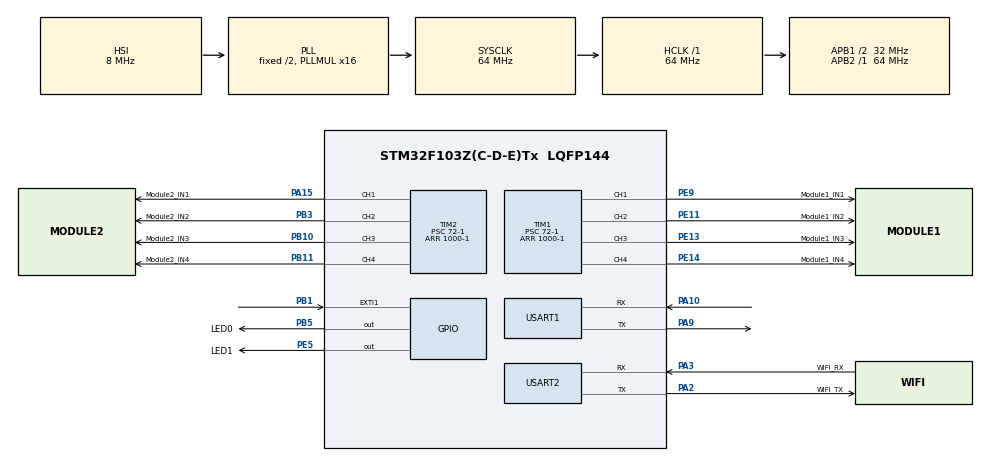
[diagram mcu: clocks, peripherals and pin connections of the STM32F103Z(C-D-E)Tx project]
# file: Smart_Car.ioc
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Dma.Request0=USART2_RX
Dma.USART2_RX.0.Direction=DMA_PERIPH_TO_MEMORY
Dma.USART2_RX.0.Instance=DMA1_Channel6
Dma.USART2_RX.0.MemDataAlignment=DMA_MDATAALIGN_BYTE
Dma.USART2_RX.0.MemInc=DMA_MINC_ENABLE
Dma.USART2_RX.0.Mode=DMA_NORMAL
Dma.USART2_RX.0.PeriphDataAlignment=DMA_PDATAALIGN_BYTE
Dma.USART2_RX.0.PeriphInc=DMA_PINC_DISABLE
Dma.USART2_RX.0.Priority=DMA_PRIORITY_LOW
Mcu.Family=STM32F1
Mcu.Name=STM32F103Z(C-D-E)Tx
Mcu.Package=LQFP144
NVIC.DMA1_Channel6_IRQn=true\:0\:0\:false\:false\:true\:false\:true
NVIC.PriorityGroup=NVIC_PRIORITYGROUP_4
NVIC.USART2_IRQn=true\:0\:0\:false\:false\:true\:true\:true
PA10.Mode=Asynchronous
PA10.Signal=USART1_RX
PA13.Mode=Serial_Wire
PA13.Signal=SYS_JTMS-SWDIO
PA14.Mode=Serial_Wire
PA14.Signal=SYS_JTCK-SWCLK
PA15.GPIO_Label=Module2_IN1
PA15.GPIO_Speed=GPIO_SPEED_FREQ_HIGH
PA15.Signal=S_TIM2_CH1_ETR
PA2.GPIO_Label=WIFI_TX
PA2.Mode=Asynchronous
PA2.Signal=USART2_TX
PA3.GPIO_Label=WIFI_RX
PA3.Mode=Asynchronous
PA3.Signal=USART2_RX
PA9.Mode=Asynchronous
PA9.Signal=USART1_TX
PB1.Signal=GPXTI1
PB10.GPIO_Label=Module2_IN3
PB10.GPIO_Speed=GPIO_SPEED_FREQ_HIGH
PB10.Signal=S_TIM2_CH3
PB11.GPIO_Label=Module2_IN4
PB11.GPIO_Speed=GPIO_SPEED_FREQ_HIGH
PB11.Signal=S_TIM2_CH4
PB3.GPIO_Label=Module2_IN2
PB3.GPIO_Speed=GPIO_SPEED_FREQ_HIGH
PB3.Signal=S_TIM2_CH2
PB5.GPIO_Label=LED0
PB5.GPIO_Speed=GPIO_SPEED_FREQ_HIGH
PB5.PinState=GPIO_PIN_SET
PB5.Signal=GPIO_Output
PE11.GPIO_Label=Module1_IN2
PE11.GPIO_Speed=GPIO_SPEED_FREQ_HIGH
PE11.Signal=S_TIM1_CH2
PE13.GPIO_Label=Module1_IN3
PE13.GPIO_Speed=GPIO_SPEED_FREQ_HIGH
PE13.Signal=S_TIM1_CH3
PE14.GPIO_Label=Module1_IN4
PE14.GPIO_Speed=GPIO_SPEED_FREQ_HIGH
PE14.Signal=S_TIM1_CH4
PE5.GPIO_Label=LED1
PE5.GPIO_Speed=GPIO_SPEED_FREQ_HIGH
PE5.PinState=GPIO_PIN_SET
PE5.Signal=GPIO_Output
PE9.GPIO_Label=Module1_IN1
PE9.GPIO_Speed=GPIO_SPEED_FREQ_HIGH
PE9.Signal=S_TIM1_CH1
ProjectManager.HeapSize=0x200
ProjectManager.StackSize=0x400
ProjectManager.TargetToolchain=MDK-ARM V5
RCC.AHBFreq_Value=64000000
RCC.APB1CLKDivider=RCC_HCLK_DIV2
RCC.APB1Freq_Value=32000000
RCC.APB1TimFreq_Value=64000000
RCC.APB2Freq_Value=64000000
RCC.APB2TimFreq_Value=64000000
RCC.HCLKFreq_Value=64000000
RCC.PLLMUL=RCC_PLL_MUL16
RCC.SYSCLKFreq_VALUE=64000000
RCC.SYSCLKSource=RCC_SYSCLKSOURCE_PLLCLK
RCC.USBFreq_Value=64000000
SH.S_TIM1_CH1.0=TIM1_CH1,PWM Generation1 CH1
SH.S_TIM1_CH2.0=TIM1_CH2,PWM Generation2 CH2
SH.S_TIM1_CH3.0=TIM1_CH3,PWM Generation3 CH3
SH.S_TIM1_CH4.0=TIM1_CH4,PWM Generation4 CH4
SH.S_TIM2_CH1_ETR.0=TIM2_CH1,PWM Generation1 CH1
SH.S_TIM2_CH2.0=TIM2_CH2,PWM Generation2 CH2
SH.S_TIM2_CH3.0=TIM2_CH3,PWM Generation3 CH3
SH.S_TIM2_CH4.0=TIM2_CH4,PWM Generation4 CH4
TIM1.Channel-PWM\ Generation1\ CH1=TIM_CHANNEL_1
TIM1.Channel-PWM\ Generation2\ CH2=TIM_CHANNEL_2
TIM1.Channel-PWM\ Generation3\ CH3=TIM_CHANNEL_3
TIM1.Channel-PWM\ Generation4\ CH4=TIM_CHANNEL_4
TIM1.Period=1000-1
TIM1.Prescaler=72-1
TIM2.Channel-PWM\ Generation1\ CH1=TIM_CHANNEL_1
TIM2.Channel-PWM\ Generation2\ CH2=TIM_CHANNEL_2
TIM2.Channel-PWM\ Generation3\ CH3=TIM_CHANNEL_3
TIM2.Channel-PWM\ Generation4\ CH4=TIM_CHANNEL_4
TIM2.Period=1000-1
TIM2.Prescaler=72-1
USART1.VirtualMode=VM_ASYNC
USART2.VirtualMode=VM_ASYNC
board=custom

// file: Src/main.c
/* USER CODE BEGIN Header */
/**
  ******************************************************************************
  * @file           : main.c
  * @brief          : Main program body
  ******************************************************************************
  * @attention
  *
  * <h2><center>&copy; Copyright (c) 2020 STMicroelectronics.
  * All rights reserved.</center></h2>
  *
  * This software component is licensed by ST under BSD 3-Clause license,
  * the "License"; You may not use this file except in compliance with the
  * License. You may obtain a copy of the License at:
  *                        opensource.org/licenses/BSD-3-Clause
  *
  ******************************************************************************
  */
/* USER CODE END Header */

#include "main.h"
#include "dma.h"
#include "tim.h"
#include "usart.h"
#include "gpio.h"

/* USER CODE BEGIN Includes */
#include "bsp_irda.h"
#include "esp8266.h"
/* USER CODE END Includes */

/* USER CODE BEGIN PV */
uint8_t isr_cnt;  /* 用于计算进了多少次中断 */
/* USER CODE END PV */

void SystemClock_Config(void);

/* USER CODE BEGIN 0 */
#define LED1_TOGGLE     HAL_GPIO_TogglePin(LED0_GPIO_Port,LED0_Pin)                // 输出反转

/* USER CODE END 0 */

int main(void)
{
    /* USER CODE BEGIN 1 */
    uint8_t key_val;
    /* USER CODE END 1 */

    /* MCU Configuration--------------------------------------------------------*/

    /* Reset of all peripherals, Initializes the Flash interface and the Systick. */
    HAL_Init();

    /* Configure the system clock */
    SystemClock_Config();

    /* Initialize all configured peripherals */
    MX_GPIO_Init();
    MX_DMA_Init();
    MX_USART1_UART_Init();
    MX_TIM1_Init();
    MX_TIM2_Init();
    MX_USART2_UART_Init();
    /* USER CODE BEGIN 2 */
    printf("ESP8266\n");
    //启动ESP8266
    wifi_send_cmd("AT+RST\r\n");
    Init_ESP8266_AP_Mode();
		HAL_GPIO_WritePin(LED1_GPIO_Port,LED1_Pin,GPIO_PIN_SET);
    /* USER CODE END 2 */

    /* Infinite loop */
    while (1)
    {

        /* USER CODE BEGIN 3 */
        ESP8266_AP_Mode_Setting();
        timer_loop();
    }

    /* USER CODE END 3 */
}

void SystemClock_Config(void)
{
    RCC_OscInitTypeDef RCC_OscInitStruct = {0};
    RCC_ClkInitTypeDef RCC_ClkInitStruct = {0};

    /** Initializes the CPU, AHB and APB busses clocks
    */
    RCC_OscInitStruct.OscillatorType = RCC_OSCILLATORTYPE_HSI;
    RCC_OscInitStruct.HSIState = RCC_HSI_ON;
    RCC_OscInitStruct.HSICalibrationValue = RCC_HSICALIBRATION_DEFAULT;
    RCC_OscInitStruct.PLL.PLLState = RCC_PLL_ON;
    RCC_OscInitStruct.PLL.PLLSource = RCC_PLLSOURCE_HSI_DIV2;
    RCC_OscInitStruct.PLL.PLLMUL = RCC_PLL_MUL16;

    if (HAL_RCC_OscConfig(&RCC_OscInitStruct) != HAL_OK)
    {
        Error_Handler();
    }

    /** Initializes the CPU, AHB and APB busses clocks
    */
    RCC_ClkInitStruct.ClockType = RCC_CLOCKTYPE_HCLK | RCC_CLOCKTYPE_SYSCLK
                                  | RCC_CLOCKTYPE_PCLK1 | RCC_CLOCKTYPE_PCLK2;
    RCC_ClkInitStruct.SYSCLKSource = RCC_SYSCLKSOURCE_PLLCLK;
    RCC_ClkInitStruct.AHBCLKDivider = RCC_SYSCLK_DIV1;
    RCC_ClkInitStruct.APB1CLKDivider = RCC_HCLK_DIV2;
    RCC_ClkInitStruct.APB2CLKDivider = RCC_HCLK_DIV1;

    if (HAL_RCC_ClockConfig(&RCC_ClkInitStruct, FLASH_LATENCY_2) != HAL_OK)
    {
        Error_Handler();
    }
}

void Error_Handler(void)
{
}

/************************ (C) COPYRIGHT STMicroelectronics *****END OF FILE****/
